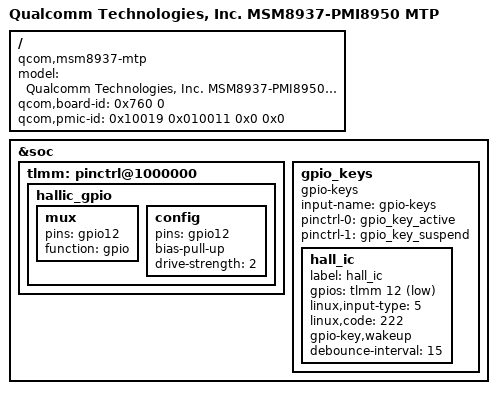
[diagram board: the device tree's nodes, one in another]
/*
 * Copyright (c) 2015, The Linux Foundation. All rights reserved.
 *
 * This program is free software; you can redistribute it and/or modify
 * it under the terms of the GNU General Public License version 2 and
 * only version 2 as published by the Free Software Foundation.
 *
 * This program is distributed in the hope that it will be useful,
 * but WITHOUT ANY WARRANTY; without even the implied warranty of
 * MERCHANTABILITY or FITNESS FOR A PARTICULAR PURPOSE.  See the
 * GNU General Public License for more details.
 */

/dts-v1/;

#include "../../qcom/msm8937.dtsi"
#include "../../qcom/msm-pmi8950.dtsi"
#include "../msm8937-lge-common/msm8937-lge.dtsi"
#include "msm8937-ph2n_mpcs_us.dtsi"
#include "msm8937-ph2n_mpcs_us-fingerprint.dtsi"

/ {
	model = "Qualcomm Technologies, Inc. MSM8937-PMI8950 MTP";
	compatible = "qcom,msm8937-mtp", "qcom,msm8937", "qcom,mtp";
	qcom,board-id= <0x760 0>;
	qcom,pmic-id = <0x10019 0x010011 0x0 0x0>;
};

&soc {
	tlmm: pinctrl@1000000 {
		hallic_gpio {
			mux {
				pins = "gpio12";
				function = "gpio";
			};
			config {
				pins = "gpio12";
				bias-pull-up; /* PULL UP */
				drive-strength = <2>; /* 2 MA */
			};
		};
	};

	gpio_keys {
		compatible = "gpio-keys";
		input-name = "gpio-keys";
		pinctrl-names = "tlmm_gpio_key_active","tlmm_gpio_key_suspend";
		pinctrl-0 = <&gpio_key_active>;
		pinctrl-1 = <&gpio_key_suspend>;

		hall_ic {
			label = "hall_ic";
			gpios = <&tlmm 12 0x1>;
			linux,input-type = <5>;
			linux,code = <222>;
			gpio-key,wakeup;
			debounce-interval = <15>;
		};
	};
};
